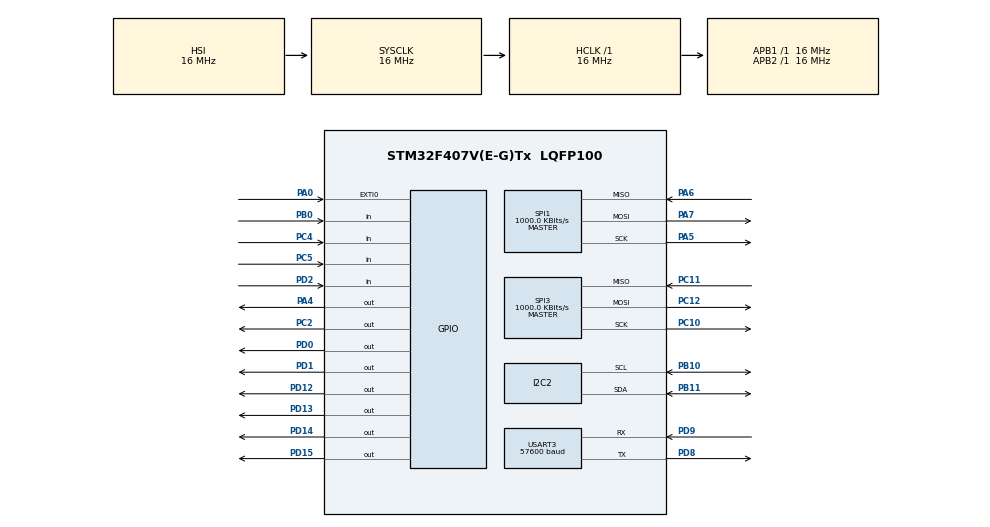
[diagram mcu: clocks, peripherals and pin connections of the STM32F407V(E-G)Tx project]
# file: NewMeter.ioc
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FREERTOS.INCLUDE_vTaskDelayUntil=1
FREERTOS.INCLUDE_xTaskGetHandle=1
FREERTOS.Tasks01=task_atm90e36a,0,1536,start_atm90e36a_task,As weak,NULL,Dynamic,NULL,NULL;task_uart,0,1024,start_uart_task,As weak,NULL,Dynamic,NULL,NULL;task_leds,0,1024,start_leds_task,As weak,NULL,Dynamic,NULL,NULL;task_sx1278,0,1024,start_sx1278_task,As weak,NULL,Dynamic,NULL,NULL
FREERTOS.configENABLE_FPU=1
FREERTOS.configQUEUE_REGISTRY_SIZE=16
FREERTOS.configTIMER_QUEUE_LENGTH=16
FREERTOS.configTOTAL_HEAP_SIZE=32768
FREERTOS.configUSE_COUNTING_SEMAPHORES=1
FREERTOS.configUSE_TIMERS=1
Mcu.Family=STM32F4
Mcu.Name=STM32F407V(E-G)Tx
Mcu.Package=LQFP100
NVIC.I2C2_EV_IRQn=true\:12\:0\:true\:false\:true\:false\:true\:true
NVIC.PriorityGroup=NVIC_PRIORITYGROUP_4
NVIC.SPI1_IRQn=true\:10\:0\:true\:false\:true\:false\:true\:true
NVIC.SPI3_IRQn=true\:10\:0\:true\:false\:true\:false\:true\:true
NVIC.TIM1_UP_TIM10_IRQn=true\:0\:0\:false\:false\:true\:false\:false\:true
NVIC.TIM2_IRQn=true\:12\:0\:true\:false\:true\:false\:true\:true
NVIC.TIM3_IRQn=true\:13\:0\:true\:false\:true\:false\:true\:true
NVIC.TimeBase=TIM1_UP_TIM10_IRQn
NVIC.TimeBaseIP=TIM1
NVIC.USART3_IRQn=true\:10\:0\:true\:false\:true\:false\:true\:true
PA0-WKUP.Signal=GPXTI0
PA13.Mode=Serial_Wire
PA13.Signal=SYS_JTMS-SWDIO
PA14.Mode=Serial_Wire
PA14.Signal=SYS_JTCK-SWCLK
PA4.GPIO_ModeDefaultOutputPP=GPIO_MODE_OUTPUT_OD
PA4.GPIO_PuPd=GPIO_PULLUP
PA4.PinState=GPIO_PIN_SET
PA4.Signal=GPIO_Output
PA5.Mode=Full_Duplex_Master
PA5.Signal=SPI1_SCK
PA6.Mode=Full_Duplex_Master
PA6.Signal=SPI1_MISO
PA7.Mode=Full_Duplex_Master
PA7.Signal=SPI1_MOSI
PB0.Signal=GPIO_Input
PB10.Mode=I2C
PB10.Signal=I2C2_SCL
PB11.Mode=I2C
PB11.Signal=I2C2_SDA
PC10.Mode=Full_Duplex_Master
PC10.Signal=SPI3_SCK
PC11.Mode=Full_Duplex_Master
PC11.Signal=SPI3_MISO
PC12.Mode=Full_Duplex_Master
PC12.Signal=SPI3_MOSI
PC2.GPIO_Speed=GPIO_SPEED_FREQ_MEDIUM
PC2.PinState=GPIO_PIN_SET
PC2.Signal=GPIO_Output
PC4.Signal=GPIO_Input
PC5.Signal=GPIO_Input
PD0.GPIO_ModeDefaultOutputPP=GPIO_MODE_OUTPUT_PP
PD0.GPIO_PuPd=GPIO_NOPULL
PD0.GPIO_Speed=GPIO_SPEED_FREQ_MEDIUM
PD0.PinState=GPIO_PIN_SET
PD0.Signal=GPIO_Output
PD1.GPIO_ModeDefaultOutputPP=GPIO_MODE_OUTPUT_OD
PD1.GPIO_PuPd=GPIO_PULLUP
PD1.PinState=GPIO_PIN_SET
PD1.Signal=GPIO_Output
PD12.Signal=GPIO_Output
PD13.Signal=GPIO_Output
PD14.Signal=GPIO_Output
PD15.Signal=GPIO_Output
PD2.Signal=GPIO_Input
PD8.Mode=Asynchronous
PD8.Signal=USART3_TX
PD9.Mode=Asynchronous
PD9.Signal=USART3_RX
ProjectManager.HeapSize=0x200
ProjectManager.StackSize=0x400
ProjectManager.TargetToolchain=STM32CubeIDE
RCC.AHBFreq_Value=16000000
RCC.APB1Freq_Value=16000000
RCC.APB2Freq_Value=16000000
RCC.CortexFreq_Value=16000000
RCC.HSE_VALUE=25000000
RCC.HSI_VALUE=16000000
RCC.LSE_VALUE=32768
RCC.SYSCLKFreq_VALUE=16000000
RCC.VCOOutputFreq_Value=192000000
SPI1.BaudRatePrescaler=SPI_BAUDRATEPRESCALER_16
SPI1.CLKPhase=SPI_PHASE_2EDGE
SPI1.CLKPolarity=SPI_POLARITY_HIGH
SPI1.CalculateBaudRate=1000.0 KBits/s
SPI1.DataSize=SPI_DATASIZE_16BIT
SPI1.Direction=SPI_DIRECTION_2LINES
SPI1.FirstBit=SPI_FIRSTBIT_MSB
SPI1.Mode=SPI_MODE_MASTER
SPI1.VirtualType=VM_MASTER
SPI3.BaudRatePrescaler=SPI_BAUDRATEPRESCALER_16
SPI3.CalculateBaudRate=1000.0 KBits/s
SPI3.Direction=SPI_DIRECTION_2LINES
SPI3.Mode=SPI_MODE_MASTER
SPI3.VirtualType=VM_MASTER
TIM2.AutoReloadPreload=TIM_AUTORELOAD_PRELOAD_ENABLE
TIM2.Period=1000
TIM2.Prescaler=1600
TIM3.AutoReloadPreload=TIM_AUTORELOAD_PRELOAD_ENABLE
TIM3.Period=10000
TIM3.Prescaler=1600
USART3.BaudRate=57600
USART3.VirtualMode=VM_ASYNC
VP_FREERTOS_VS_CMSIS_V1.Mode=CMSIS_V1
VP_SYS_VS_tim1.Mode=TIM1
VP_TIM2_VS_ClockSourceINT.Mode=Internal
VP_TIM3_VS_ClockSourceINT.Mode=Internal
board=custom

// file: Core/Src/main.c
/* USER CODE BEGIN Header */
/**
  ******************************************************************************
  * @file           : main.c
  * @brief          : Main program body
  ******************************************************************************
  * @attention
  *
  * <h2><center>&copy; Copyright (c) 2020 STMicroelectronics.
  * All rights reserved.</center></h2>
  *
  * This software component is licensed by ST under BSD 3-Clause license,
  * the "License"; You may not use this file except in compliance with the
  * License. You may obtain a copy of the License at:
  *                        opensource.org/licenses/BSD-3-Clause
  *
  ******************************************************************************
  */
/* USER CODE END Header */
#include "main.h"
#include "cmsis_os.h"

I2C_HandleTypeDef hi2c2;

SPI_HandleTypeDef hspi1;
SPI_HandleTypeDef hspi3;

TIM_HandleTypeDef htim2;
TIM_HandleTypeDef htim3;

UART_HandleTypeDef huart3;

osThreadId task_atm90e36aHandle;
osThreadId task_uartHandle;
osThreadId task_ledsHandle;
osThreadId task_sx1278Handle;
/* USER CODE BEGIN PV */
SemaphoreHandle_t SyncMeasureSem;

/* USER CODE END PV */

void SystemClock_Config(void);
static void MX_GPIO_Init(void);
static void MX_I2C2_Init(void);
static void MX_SPI1_Init(void);
static void MX_TIM2_Init(void);
static void MX_USART3_UART_Init(void);
static void MX_TIM3_Init(void);
static void MX_SPI3_Init(void);
void start_atm90e36a_task(void const * argument);
void start_uart_task(void const * argument);
void start_leds_task(void const * argument);
void start_sx1278_task(void const * argument);

int main(void)
{

  /* MCU Configuration--------------------------------------------------------*/

  /* Reset of all peripherals, Initializes the Flash interface and the Systick. */
  HAL_Init();

  /* Configure the system clock */
  SystemClock_Config();

  /* Initialize all configured peripherals */
  MX_GPIO_Init();
  MX_I2C2_Init();
  MX_SPI1_Init();
  MX_TIM2_Init();
  MX_USART3_UART_Init();
  MX_TIM3_Init();
  MX_SPI3_Init();

  /* USER CODE BEGIN RTOS_SEMAPHORES */
  /* add semaphores, ... */
  SyncMeasureSem = xSemaphoreCreateBinary();
  /* USER CODE END RTOS_SEMAPHORES */

  /* Create the thread(s) */
  /* definition and creation of task_atm90e36a */
  osThreadDef(task_atm90e36a, start_atm90e36a_task, osPriorityNormal, 0, 1536);
  task_atm90e36aHandle = osThreadCreate(osThread(task_atm90e36a), NULL);

  /* definition and creation of task_uart */
  osThreadDef(task_uart, start_uart_task, osPriorityNormal, 0, 1024);
  task_uartHandle = osThreadCreate(osThread(task_uart), NULL);

  /* definition and creation of task_leds */
  osThreadDef(task_leds, start_leds_task, osPriorityNormal, 0, 1024);
  task_ledsHandle = osThreadCreate(osThread(task_leds), NULL);

  /* definition and creation of task_sx1278 */
  osThreadDef(task_sx1278, start_sx1278_task, osPriorityNormal, 0, 1024);
  task_sx1278Handle = osThreadCreate(osThread(task_sx1278), NULL);

  /* Start scheduler */
  osKernelStart();

  /* We should never get here as control is now taken by the scheduler */
  /* Infinite loop */
  while (1)
  {

  }
}

void SystemClock_Config(void)
{
  RCC_OscInitTypeDef RCC_OscInitStruct = {0};
  RCC_ClkInitTypeDef RCC_ClkInitStruct = {0};

  /** Configure the main internal regulator output voltage
  */
  __HAL_RCC_PWR_CLK_ENABLE();
  __HAL_PWR_VOLTAGESCALING_CONFIG(PWR_REGULATOR_VOLTAGE_SCALE1);
  /** Initializes the RCC Oscillators according to the specified parameters
  * in the RCC_OscInitTypeDef structure.
  */
  RCC_OscInitStruct.OscillatorType = RCC_OSCILLATORTYPE_HSI;
  RCC_OscInitStruct.HSIState = RCC_HSI_ON;
  RCC_OscInitStruct.HSICalibrationValue = RCC_HSICALIBRATION_DEFAULT;
  RCC_OscInitStruct.PLL.PLLState = RCC_PLL_NONE;
  if (HAL_RCC_OscConfig(&RCC_OscInitStruct) != HAL_OK)
  {
    Error_Handler();
  }
  /** Initializes the CPU, AHB and APB buses clocks
  */
  RCC_ClkInitStruct.ClockType = RCC_CLOCKTYPE_HCLK|RCC_CLOCKTYPE_SYSCLK
                              |RCC_CLOCKTYPE_PCLK1|RCC_CLOCKTYPE_PCLK2;
  RCC_ClkInitStruct.SYSCLKSource = RCC_SYSCLKSOURCE_HSI;
  RCC_ClkInitStruct.AHBCLKDivider = RCC_SYSCLK_DIV1;
  RCC_ClkInitStruct.APB1CLKDivider = RCC_HCLK_DIV1;
  RCC_ClkInitStruct.APB2CLKDivider = RCC_HCLK_DIV1;

  if (HAL_RCC_ClockConfig(&RCC_ClkInitStruct, FLASH_LATENCY_0) != HAL_OK)
  {
    Error_Handler();
  }
}

static void MX_I2C2_Init(void)
{

  hi2c2.Instance = I2C2;
  hi2c2.Init.ClockSpeed = 100000;
  hi2c2.Init.DutyCycle = I2C_DUTYCYCLE_2;
  hi2c2.Init.OwnAddress1 = 0;
  hi2c2.Init.AddressingMode = I2C_ADDRESSINGMODE_7BIT;
  hi2c2.Init.DualAddressMode = I2C_DUALADDRESS_DISABLE;
  hi2c2.Init.OwnAddress2 = 0;
  hi2c2.Init.GeneralCallMode = I2C_GENERALCALL_DISABLE;
  hi2c2.Init.NoStretchMode = I2C_NOSTRETCH_DISABLE;
  if (HAL_I2C_Init(&hi2c2) != HAL_OK)
  {
    Error_Handler();
  }

}

static void MX_SPI1_Init(void)
{

  /* SPI1 parameter configuration*/
  hspi1.Instance = SPI1;
  hspi1.Init.Mode = SPI_MODE_MASTER;
  hspi1.Init.Direction = SPI_DIRECTION_2LINES;
  hspi1.Init.DataSize = SPI_DATASIZE_16BIT;
  hspi1.Init.CLKPolarity = SPI_POLARITY_HIGH;
  hspi1.Init.CLKPhase = SPI_PHASE_2EDGE;
  hspi1.Init.NSS = SPI_NSS_SOFT;
  hspi1.Init.BaudRatePrescaler = SPI_BAUDRATEPRESCALER_16;
  hspi1.Init.FirstBit = SPI_FIRSTBIT_MSB;
  hspi1.Init.TIMode = SPI_TIMODE_DISABLE;
  hspi1.Init.CRCCalculation = SPI_CRCCALCULATION_DISABLE;
  hspi1.Init.CRCPolynomial = 10;
  if (HAL_SPI_Init(&hspi1) != HAL_OK)
  {
    Error_Handler();
  }

}

static void MX_SPI3_Init(void)
{

  /* SPI3 parameter configuration*/
  hspi3.Instance = SPI3;
  hspi3.Init.Mode = SPI_MODE_MASTER;
  hspi3.Init.Direction = SPI_DIRECTION_2LINES;
  hspi3.Init.DataSize = SPI_DATASIZE_8BIT;
  hspi3.Init.CLKPolarity = SPI_POLARITY_LOW;
  hspi3.Init.CLKPhase = SPI_PHASE_1EDGE;
  hspi3.Init.NSS = SPI_NSS_SOFT;
  hspi3.Init.BaudRatePrescaler = SPI_BAUDRATEPRESCALER_16;
  hspi3.Init.FirstBit = SPI_FIRSTBIT_MSB;
  hspi3.Init.TIMode = SPI_TIMODE_DISABLE;
  hspi3.Init.CRCCalculation = SPI_CRCCALCULATION_DISABLE;
  hspi3.Init.CRCPolynomial = 10;
  if (HAL_SPI_Init(&hspi3) != HAL_OK)
  {
    Error_Handler();
  }

}

static void MX_TIM2_Init(void)
{

  TIM_ClockConfigTypeDef sClockSourceConfig = {0};
  TIM_MasterConfigTypeDef sMasterConfig = {0};

  htim2.Instance = TIM2;
  htim2.Init.Prescaler = 1600;
  htim2.Init.CounterMode = TIM_COUNTERMODE_UP;
  htim2.Init.Period = 1000;
  htim2.Init.ClockDivision = TIM_CLOCKDIVISION_DIV1;
  htim2.Init.AutoReloadPreload = TIM_AUTORELOAD_PRELOAD_ENABLE;
  if (HAL_TIM_Base_Init(&htim2) != HAL_OK)
  {
    Error_Handler();
  }
  sClockSourceConfig.ClockSource = TIM_CLOCKSOURCE_INTERNAL;
  if (HAL_TIM_ConfigClockSource(&htim2, &sClockSourceConfig) != HAL_OK)
  {
    Error_Handler();
  }
  sMasterConfig.MasterOutputTrigger = TIM_TRGO_RESET;
  sMasterConfig.MasterSlaveMode = TIM_MASTERSLAVEMODE_DISABLE;
  if (HAL_TIMEx_MasterConfigSynchronization(&htim2, &sMasterConfig) != HAL_OK)
  {
    Error_Handler();
  }

}

static void MX_TIM3_Init(void)
{

  TIM_ClockConfigTypeDef sClockSourceConfig = {0};
  TIM_MasterConfigTypeDef sMasterConfig = {0};

  htim3.Instance = TIM3;
  htim3.Init.Prescaler = 1600;
  htim3.Init.CounterMode = TIM_COUNTERMODE_UP;
  htim3.Init.Period = 10000;
  htim3.Init.ClockDivision = TIM_CLOCKDIVISION_DIV1;
  htim3.Init.AutoReloadPreload = TIM_AUTORELOAD_PRELOAD_ENABLE;
  if (HAL_TIM_Base_Init(&htim3) != HAL_OK)
  {
    Error_Handler();
  }
  sClockSourceConfig.ClockSource = TIM_CLOCKSOURCE_INTERNAL;
  if (HAL_TIM_ConfigClockSource(&htim3, &sClockSourceConfig) != HAL_OK)
  {
    Error_Handler();
  }
  sMasterConfig.MasterOutputTrigger = TIM_TRGO_RESET;
  sMasterConfig.MasterSlaveMode = TIM_MASTERSLAVEMODE_DISABLE;
  if (HAL_TIMEx_MasterConfigSynchronization(&htim3, &sMasterConfig) != HAL_OK)
  {
    Error_Handler();
  }

}

static void MX_USART3_UART_Init(void)
{

  huart3.Instance = USART3;
  huart3.Init.BaudRate = 57600;
  huart3.Init.WordLength = UART_WORDLENGTH_8B;
  huart3.Init.StopBits = UART_STOPBITS_1;
  huart3.Init.Parity = UART_PARITY_NONE;
  huart3.Init.Mode = UART_MODE_TX_RX;
  huart3.Init.HwFlowCtl = UART_HWCONTROL_NONE;
  huart3.Init.OverSampling = UART_OVERSAMPLING_16;
  if (HAL_UART_Init(&huart3) != HAL_OK)
  {
    Error_Handler();
  }

}

static void MX_GPIO_Init(void)
{
  GPIO_InitTypeDef GPIO_InitStruct = {0};

  /* GPIO Ports Clock Enable */
  __HAL_RCC_GPIOC_CLK_ENABLE();
  __HAL_RCC_GPIOA_CLK_ENABLE();
  __HAL_RCC_GPIOB_CLK_ENABLE();
  __HAL_RCC_GPIOD_CLK_ENABLE();

  /*Configure GPIO pin Output Level */
  HAL_GPIO_WritePin(GPIOC, GPIO_PIN_2, GPIO_PIN_SET);

  /*Configure GPIO pin Output Level */
  HAL_GPIO_WritePin(GPIOA, GPIO_PIN_4, GPIO_PIN_SET);

  /*Configure GPIO pin Output Level */
  HAL_GPIO_WritePin(GPIOD, GPIO_PIN_12|GPIO_PIN_13|GPIO_PIN_14|GPIO_PIN_15, GPIO_PIN_RESET);

  /*Configure GPIO pin Output Level */
  HAL_GPIO_WritePin(GPIOD, GPIO_PIN_0|GPIO_PIN_1, GPIO_PIN_SET);

  /*Configure GPIO pin : PC2 */
  GPIO_InitStruct.Pin = GPIO_PIN_2;
  GPIO_InitStruct.Mode = GPIO_MODE_OUTPUT_PP;
  GPIO_InitStruct.Pull = GPIO_NOPULL;
  GPIO_InitStruct.Speed = GPIO_SPEED_FREQ_MEDIUM;
  HAL_GPIO_Init(GPIOC, &GPIO_InitStruct);

  /*Configure GPIO pin : PA0 */
  GPIO_InitStruct.Pin = GPIO_PIN_0;
  GPIO_InitStruct.Mode = GPIO_MODE_IT_RISING;
  GPIO_InitStruct.Pull = GPIO_NOPULL;
  HAL_GPIO_Init(GPIOA, &GPIO_InitStruct);

  /*Configure GPIO pin : PA4 */
  GPIO_InitStruct.Pin = GPIO_PIN_4;
  GPIO_InitStruct.Mode = GPIO_MODE_OUTPUT_OD;
  GPIO_InitStruct.Pull = GPIO_PULLUP;
  GPIO_InitStruct.Speed = GPIO_SPEED_FREQ_LOW;
  HAL_GPIO_Init(GPIOA, &GPIO_InitStruct);

  /*Configure GPIO pins : PC4 PC5 */
  GPIO_InitStruct.Pin = GPIO_PIN_4|GPIO_PIN_5;
  GPIO_InitStruct.Mode = GPIO_MODE_INPUT;
  GPIO_InitStruct.Pull = GPIO_NOPULL;
  HAL_GPIO_Init(GPIOC, &GPIO_InitStruct);

  /*Configure GPIO pin : PB0 */
  GPIO_InitStruct.Pin = GPIO_PIN_0;
  GPIO_InitStruct.Mode = GPIO_MODE_INPUT;
  GPIO_InitStruct.Pull = GPIO_NOPULL;
  HAL_GPIO_Init(GPIOB, &GPIO_InitStruct);

  /*Configure GPIO pins : PD12 PD13 PD14 PD15 */
  GPIO_InitStruct.Pin = GPIO_PIN_12|GPIO_PIN_13|GPIO_PIN_14|GPIO_PIN_15;
  GPIO_InitStruct.Mode = GPIO_MODE_OUTPUT_PP;
  GPIO_InitStruct.Pull = GPIO_NOPULL;
  GPIO_InitStruct.Speed = GPIO_SPEED_FREQ_LOW;
  HAL_GPIO_Init(GPIOD, &GPIO_InitStruct);

  /*Configure GPIO pin : PD0 */
  GPIO_InitStruct.Pin = GPIO_PIN_0;
  GPIO_InitStruct.Mode = GPIO_MODE_OUTPUT_PP;
  GPIO_InitStruct.Pull = GPIO_NOPULL;
  GPIO_InitStruct.Speed = GPIO_SPEED_FREQ_MEDIUM;
  HAL_GPIO_Init(GPIOD, &GPIO_InitStruct);

  /*Configure GPIO pin : PD1 */
  GPIO_InitStruct.Pin = GPIO_PIN_1;
  GPIO_InitStruct.Mode = GPIO_MODE_OUTPUT_OD;
  GPIO_InitStruct.Pull = GPIO_PULLUP;
  GPIO_InitStruct.Speed = GPIO_SPEED_FREQ_LOW;
  HAL_GPIO_Init(GPIOD, &GPIO_InitStruct);

  /*Configure GPIO pin : PD2 */
  GPIO_InitStruct.Pin = GPIO_PIN_2;
  GPIO_InitStruct.Mode = GPIO_MODE_INPUT;
  GPIO_InitStruct.Pull = GPIO_NOPULL;
  HAL_GPIO_Init(GPIOD, &GPIO_InitStruct);

}

__weak void start_atm90e36a_task(void const * argument)
{
  for(;;)
  {
    osDelay(1);
  }
}

__weak void start_uart_task(void const * argument)
{
  for(;;)
  {
    osDelay(1);
  }
}

__weak void start_leds_task(void const * argument)
{
  for(;;)
  {
    osDelay(1);
  }
}

__weak void start_sx1278_task(void const * argument)
{
  for(;;)
  {
    osDelay(1);
  }
}

 /**
  * @brief  Period elapsed callback in non blocking mode
  * @note   This function is called  when TIM1 interrupt took place, inside
  * HAL_TIM_IRQHandler(). It makes a direct call to HAL_IncTick() to increment
  * a global variable "uwTick" used as application time base.
  * @param  htim : TIM handle
  * @retval None
  */
void HAL_TIM_PeriodElapsedCallback(TIM_HandleTypeDef *htim)
{
  if (htim->Instance == TIM1) {
    HAL_IncTick();
  }
}

void Error_Handler(void)
{
}

/************************ (C) COPYRIGHT STMicroelectronics *****END OF FILE****/

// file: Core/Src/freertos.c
/* USER CODE BEGIN Header */
/**
  ******************************************************************************
  * File Name          : freertos.c
  * Description        : Code for freertos applications
  ******************************************************************************
  * @attention
  *
  * <h2><center>&copy; Copyright (c) 2020 STMicroelectronics.
  * All rights reserved.</center></h2>
  *
  * This software component is licensed by ST under Ultimate Liberty license
  * SLA0044, the "License"; You may not use this file except in compliance with
  * the License. You may obtain a copy of the License at:
  *                             www.st.com/SLA0044
  *
  ******************************************************************************
  */
/* USER CODE END Header */

#include "FreeRTOS.h"
#include "task.h"
#include "main.h"

/* GetIdleTaskMemory prototype (linked to static allocation support) */
void vApplicationGetIdleTaskMemory( StaticTask_t **ppxIdleTaskTCBBuffer, StackType_t **ppxIdleTaskStackBuffer, uint32_t *pulIdleTaskStackSize );

/* GetTimerTaskMemory prototype (linked to static allocation support) */
void vApplicationGetTimerTaskMemory( StaticTask_t **ppxTimerTaskTCBBuffer, StackType_t **ppxTimerTaskStackBuffer, uint32_t *pulTimerTaskStackSize );

/* USER CODE BEGIN GET_IDLE_TASK_MEMORY */
static StaticTask_t xIdleTaskTCBBuffer;
static StackType_t xIdleStack[configMINIMAL_STACK_SIZE];

void vApplicationGetIdleTaskMemory( StaticTask_t **ppxIdleTaskTCBBuffer, StackType_t **ppxIdleTaskStackBuffer, uint32_t *pulIdleTaskStackSize )
{
  *ppxIdleTaskTCBBuffer = &xIdleTaskTCBBuffer;
  *ppxIdleTaskStackBuffer = &xIdleStack[0];
  *pulIdleTaskStackSize = configMINIMAL_STACK_SIZE;
  /* place for user code */
}
/* USER CODE END GET_IDLE_TASK_MEMORY */

/* USER CODE BEGIN GET_TIMER_TASK_MEMORY */
static StaticTask_t xTimerTaskTCBBuffer;
static StackType_t xTimerStack[configTIMER_TASK_STACK_DEPTH];

void vApplicationGetTimerTaskMemory( StaticTask_t **ppxTimerTaskTCBBuffer, StackType_t **ppxTimerTaskStackBuffer, uint32_t *pulTimerTaskStackSize )
{
  *ppxTimerTaskTCBBuffer = &xTimerTaskTCBBuffer;
  *ppxTimerTaskStackBuffer = &xTimerStack[0];
  *pulTimerTaskStackSize = configTIMER_TASK_STACK_DEPTH;
  /* place for user code */
}
/* USER CODE END GET_TIMER_TASK_MEMORY */

/************************ (C) COPYRIGHT STMicroelectronics *****END OF FILE****/
